VERSION ""

NS_ :

BS_:

BU_:

BO_ 3 gnss_pos: 8 Vector__XXX
 SG_ Latitude : 5|30@0- (1,0) [-536870912|536870911] "ms arc" Vector__XXX
 SG_ Longitude : 38|31@0- (1,0) [-1073741824|1073741823] "ms arc" Vector__XXX

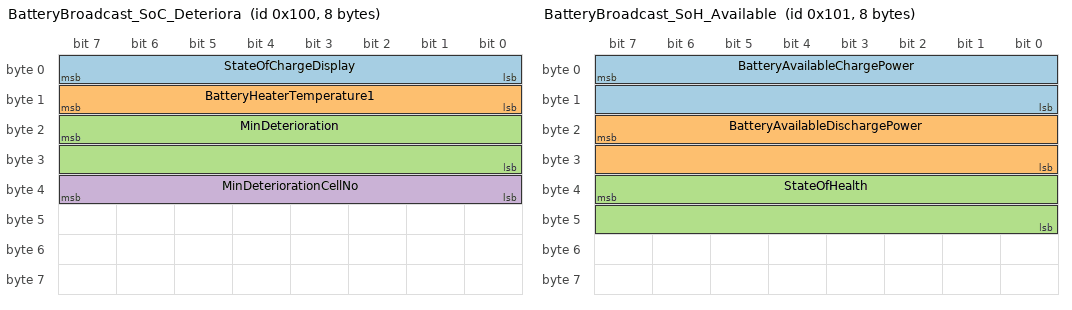
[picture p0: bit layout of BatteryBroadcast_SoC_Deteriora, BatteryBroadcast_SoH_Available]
BO_ 256 BatteryBroadcast_SoC_Deteriora: 8 Vector__XXX
 SG_ StateOfChargeDisplay : 7|8@0+ (0.5,3) [0|0] "%" Vector__XXX
 SG_ BatteryHeaterTemperature1 : 15|8@0- (1,0) [0|0] "degC" Vector__XXX
 SG_ MinDeterioration : 23|16@0+ (0.1,0) [0|100] "%" Vector__XXX
 SG_ MinDeteriorationCellNo : 39|8@0+ (1,0) [0|98] "" Vector__XXX

BO_ 257 BatteryBroadcast_SoH_Available: 8 Vector__XXX
 SG_ BatteryAvailableChargePower : 7|16@0+ (0.01,0) [0|270] "kW" Vector__XXX
 SG_ BatteryAvailableDischargePower : 23|16@0+ (0.01,0) [0|270] "kW" Vector__XXX
 SG_ StateOfHealth : 39|16@0+ (0.1,0) [0|100] "%" Vector__XXX

BO_ 512 BatteryBroadcast_CellV_Modules: 8 Vector__XXX
 SG_ CellVoltage01 m258 : 7|8@0+ (0.02,0) [2.8|4.2] "V" Vector__XXX
 SG_ CellVoltage02 m258 : 15|8@0+ (0.02,0) [2.8|4.2] "V" Vector__XXX
 SG_ CellVoltage03 m258 : 23|8@0+ (0.02,0) [2.8|4.2] "V" Vector__XXX
 SG_ CellVoltage04 m258 : 31|8@0+ (0.02,0) [2.8|4.2] "V" Vector__XXX
 SG_ CellVoltage05 m258 : 39|8@0+ (0.02,0) [2.8|4.2] "V" Vector__XXX
 SG_ CellVoltage06 m258 : 47|8@0+ (0.02,0) [2.8|4.2] "V" Vector__XXX
 SG_ CellVoltage07 m258 : 55|8@0+ (0.02,0) [2.8|4.2] "V" Vector__XXX
 SG_ CellVoltage08 m258 : 63|8@0+ (0.02,0) [2.8|4.2] "V" Vector__XXX

BO_ 513 BatteryBroadcast_CellV_Modul01: 8 Vector__XXX
 SG_ CellVoltage09 : 7|8@0+ (0.02,0) [2.8|4.2] "V" Vector__XXX
 SG_ CellVoltage10 m258 : 15|8@0+ (0.02,0) [2.8|4.2] "V" Vector__XXX
 SG_ CellVoltage11 m258 : 23|8@0+ (0.02,0) [2.8|4.2] "V" Vector__XXX
 SG_ CellVoltage12 m258 : 31|8@0+ (0.02,0) [2.8|4.2] "V" Vector__XXX
 SG_ CellVoltage13 m258 : 39|8@0+ (0.02,0) [2.8|4.2] "V" Vector__XXX
 SG_ CellVoltage14 m258 : 47|8@0+ (0.02,0) [2.8|4.2] "V" Vector__XXX
 SG_ CellVoltage15 m258 : 55|8@0+ (0.02,0) [2.8|4.2] "V" Vector__XXX
 SG_ CellVoltage16 m258 : 63|8@0+ (0.02,0) [2.8|4.2] "V" Vector__XXX

BO_ 514 BatteryBroadcast_CellV_Modul02: 8 Vector__XXX
 SG_ CellVoltage17 : 7|8@0+ (0.02,0) [2.8|4.2] "V" Vector__XXX
 SG_ CellVoltage18 m258 : 15|8@0+ (0.02,0) [2.8|4.2] "V" Vector__XXX
 SG_ CellVoltage19 m258 : 23|8@0+ (0.02,0) [2.8|4.2] "V" Vector__XXX
 SG_ CellVoltage20 : 31|8@0+ (0.02,0) [2.8|4.2] "V" Vector__XXX
 SG_ CellVoltage21 : 39|8@0+ (0.02,0) [2.4|4.8] "V" Vector__XXX
 SG_ CellVoltage22 : 47|8@0+ (0.02,0) [2.4|4.8] "V" Vector__XXX
 SG_ CellVoltage23 : 55|8@0+ (0.02,0) [2.8|4.2] "V" Vector__XXX
 SG_ CellVoltage24 : 63|8@0+ (0.02,0) [2.8|4.2] "V" Vector__XXX

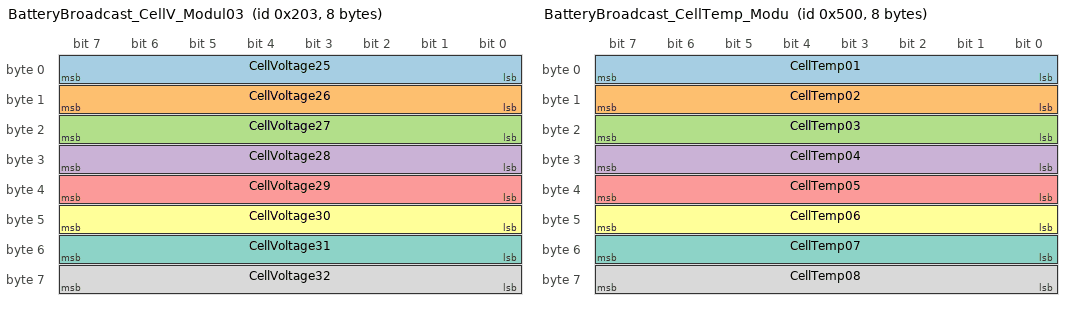
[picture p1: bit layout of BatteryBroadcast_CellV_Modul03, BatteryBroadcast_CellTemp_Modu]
BO_ 515 BatteryBroadcast_CellV_Modul03: 8 Vector__XXX
 SG_ CellVoltage25 : 7|8@0+ (0.02,0) [2.8|4.2] "V" Vector__XXX
 SG_ CellVoltage26 : 15|8@0+ (0.02,0) [2.8|4.2] "V" Vector__XXX
 SG_ CellVoltage27 : 23|8@0+ (0.02,0) [2.8|4.2] "V" Vector__XXX
 SG_ CellVoltage28 : 31|8@0+ (0.02,0) [2.8|4.2] "V" Vector__XXX
 SG_ CellVoltage29 : 39|8@0+ (0.02,0) [2.8|4.2] "V" Vector__XXX
 SG_ CellVoltage30 : 47|8@0+ (0.02,0) [2.8|4.2] "V" Vector__XXX
 SG_ CellVoltage31 : 55|8@0+ (0.02,0) [2.8|4.2] "V" Vector__XXX
 SG_ CellVoltage32 : 63|8@0+ (0.02,0) [2.8|4.2] "V" Vector__XXX

BO_ 768 BatteryBroadcast_Battery_Info_: 8 Vector__XXX
 SG_ MinCellVoltage m257 : 7|8@0+ (0.02,0) [2.8|4.2] "V" Vector__XXX
 SG_ MaxCellVoltage m257 : 15|8@0+ (0.02,0) [2.8|4.2] "V" Vector__XXX
 SG_ StateOfChargeBMS m257 : 55|8@0+ (0.5,3) [0|100] "%" Vector__XXX
 SG_ hasActiveDTC : 63|1@0+ (1,0) [0|1] "" Vector__XXX

BO_ 769 BatteryBroadcast_Battery_Inf01: 8 Vector__XXX
 SG_ BatteryMinTemperature m257 : 7|8@0- (1,0) [0|0] "degC" Vector__XXX
 SG_ BatteryMaxTemperature m257 : 15|8@0- (1,0) [0|0] "degC" Vector__XXX
 SG_ BatteryVoltageAuxillary m257 : 23|8@0+ (0.1,0) [11|14.6] "V" Vector__XXX
 SG_ BatteryFanFeedback m257 : 39|8@0+ (1,0) [0|120] "Hz" Vector__XXX
 SG_ BatteryFanStatus m257 : 47|1@0+ (1,0) [0|0] "" Vector__XXX
 SG_ NormalChargePort m257 : 53|1@0+ (1,0) [0|0] "" Vector__XXX
 SG_ RapidChargePort m257 : 54|1@0+ (1,0) [0|0] "" Vector__XXX

BO_ 770 BatteryBroadcast_Battery_Inf02: 8 Vector__XXX
 SG_ OperatingTime m257 : 7|32@0+ (0.000277778,0) [0|1000000] "hours" Vector__XXX
 SG_ MinCellVoltageCellNo m257 : 39|8@0+ (1,0) [0|0] "" Vector__XXX
 SG_ MaxCellVoltageCellNo m257 : 47|8@0+ (1,0) [0|0] "" Vector__XXX
 SG_ Charging m257 : 55|1@0+ (1,0) [0|0] "" Vector__XXX
 SG_ BMSMainRelay m257 : 48|1@0+ (1,0) [0|0] "" Vector__XXX
 SG_ BMSIgnition m257 : 50|1@0+ (1,0) [0|0] "" Vector__XXX

BO_ 771 BatteryBroadcast_Battery_Inf03: 8 Vector__XXX
 SG_ BatteryDCVoltage m257 : 7|16@0+ (0.1,0) [0|0] "V" Vector__XXX
 SG_ BatteryCurrent m257 : 23|16@0- (0.1,0) [-230|230] "A" Vector__XXX

BO_ 1024 VehicleBroadcast_Temperature_I: 8 Vector__XXX
 SG_ IndoorTemperature m256 : 7|8@0+ (0.5,-40) [-50|50] "degC" Vector__XXX
 SG_ OutdoorTemperature m256 : 15|8@0+ (0.5,-40) [-50|50] "degC" Vector__XXX
 SG_ VehicleSpeed m256 : 23|8@0+ (1,0) [0|200] "kmh" Vector__XXX

BO_ 1025 VehicleBroadCast_Tire_Info: 8 Vector__XXX
 SG_ TirePressureFrontLeft m49163 : 7|8@0+ (0.2,0) [0|120] "psi" Vector__XXX
 SG_ TirePressureFrontRight m49163 : 15|8@0+ (0.2,0) [0|120] "psi" Vector__XXX
 SG_ TirePressureBackLeft m49163 : 23|8@0+ (0.2,0) [0|120] "psi" Vector__XXX
 SG_ TirePressureBackRight m49163 : 31|8@0+ (0.2,0) [0|120] "psi" Vector__XXX
 SG_ TireTemperatureFrontLeft m49163 : 39|8@0+ (1,-50) [-40|65] "degC" Vector__XXX
 SG_ TireTemperatureFrontRight m49163 : 47|8@0+ (1,-50) [-40|65] "degC" Vector__XXX
 SG_ TireTemperatureBackLeft m49163 : 55|8@0+ (1,-50) [-40|65] "degC" Vector__XXX
 SG_ TireTemperatureBackRight m49163 : 63|8@0+ (1,-50) [-40|65] "degC" Vector__XXX

BO_ 1280 BatteryBroadcast_CellTemp_Modu: 8 Vector__XXX
 SG_ CellTemp01 : 7|8@0- (1,0) [-128|127] "degC" Vector__XXX
 SG_ CellTemp02 : 15|8@0- (1,0) [-128|127] "degC" Vector__XXX
 SG_ CellTemp03 : 23|8@0- (1,0) [-128|127] "degC" Vector__XXX
 SG_ CellTemp04 : 31|8@0- (1,0) [-128|127] "degC" Vector__XXX
 SG_ CellTemp05 : 39|8@0- (1,0) [-128|127] "degC" Vector__XXX
 SG_ CellTemp06 : 47|8@0- (1,0) [-128|127] "degC" Vector__XXX
 SG_ CellTemp07 : 55|8@0- (1,0) [-128|127] "degC" Vector__XXX
 SG_ CellTemp08 : 63|8@0- (1,0) [-128|127] "degC" Vector__XXX

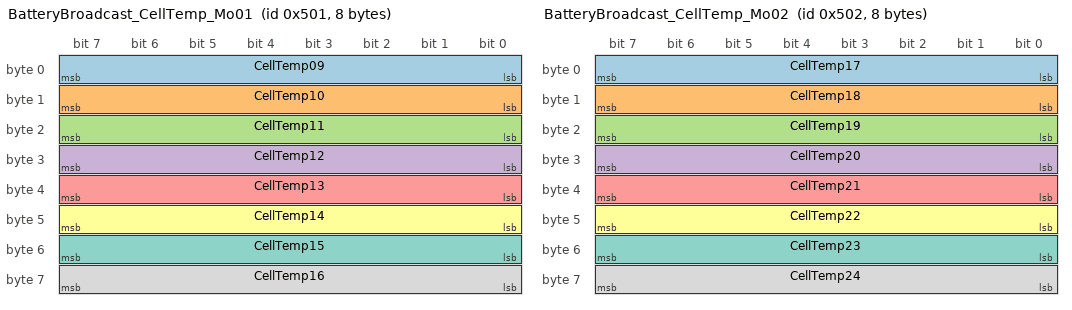
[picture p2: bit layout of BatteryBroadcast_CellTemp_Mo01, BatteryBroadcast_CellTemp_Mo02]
BO_ 1281 BatteryBroadcast_CellTemp_Mo01: 8 Vector__XXX
 SG_ CellTemp09 : 7|8@0- (1,0) [-128|127] "degC" Vector__XXX
 SG_ CellTemp10 : 15|8@0- (1,0) [-128|127] "degC" Vector__XXX
 SG_ CellTemp11 : 23|8@0- (1,0) [-128|127] "degC" Vector__XXX
 SG_ CellTemp12 : 31|8@0- (1,0) [-128|127] "degC" Vector__XXX
 SG_ CellTemp13 : 39|8@0- (1,0) [-128|127] "degC" Vector__XXX
 SG_ CellTemp14 : 47|8@0- (1,0) [-128|127] "degC" Vector__XXX
 SG_ CellTemp15 : 55|8@0- (1,0) [-128|127] "degC" Vector__XXX
 SG_ CellTemp16 : 63|8@0- (1,0) [-128|127] "degC" Vector__XXX

BO_ 1282 BatteryBroadcast_CellTemp_Mo02: 8 Vector__XXX
 SG_ CellTemp17 : 7|8@0- (1,0) [-128|127] "degC" Vector__XXX
 SG_ CellTemp18 : 15|8@0- (1,0) [-128|127] "degC" Vector__XXX
 SG_ CellTemp19 : 23|8@0- (1,0) [-128|127] "degC" Vector__XXX
 SG_ CellTemp20 : 31|8@0- (1,0) [-128|127] "degC" Vector__XXX
 SG_ CellTemp21 : 39|8@0- (1,0) [-128|127] "degC" Vector__XXX
 SG_ CellTemp22 : 47|8@0- (1,0) [-128|127] "degC" Vector__XXX
 SG_ CellTemp23 : 55|8@0- (1,0) [-128|127] "degC" Vector__XXX
 SG_ CellTemp24 : 63|8@0- (1,0) [-128|127] "degC" Vector__XXX

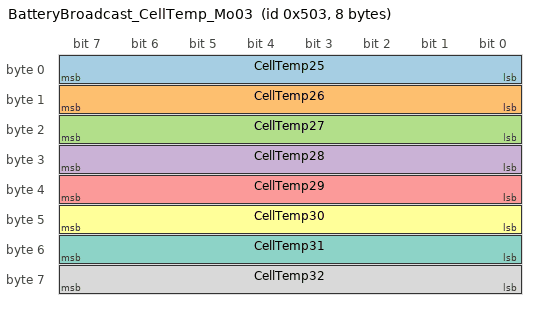
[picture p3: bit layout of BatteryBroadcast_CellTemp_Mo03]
BO_ 1283 BatteryBroadcast_CellTemp_Mo03: 8 Vector__XXX
 SG_ CellTemp25 : 7|8@0- (1,0) [-128|127] "degC" Vector__XXX
 SG_ CellTemp26 : 15|8@0- (1,0) [-128|127] "degC" Vector__XXX
 SG_ CellTemp27 : 23|8@0- (1,0) [-128|127] "degC" Vector__XXX
 SG_ CellTemp28 : 31|8@0- (1,0) [-128|127] "degC" Vector__XXX
 SG_ CellTemp29 : 39|8@0- (1,0) [-128|127] "degC" Vector__XXX
 SG_ CellTemp30 : 47|8@0- (1,0) [-128|127] "degC" Vector__XXX
 SG_ CellTemp31 : 55|8@0- (1,0) [-128|127] "degC" Vector__XXX
 SG_ CellTemp32 : 63|8@0- (1,0) [-128|127] "degC" Vector__XXX

BA_DEF_ BO_  "GenMsgCycleTime" INT 0 10000;
BA_DEF_DEF_  "GenMsgCycleTime" 0;
BA_ "GenMsgCycleTime" BO_ 3 250;
BA_ "GenMsgCycleTime" BO_ 256 500;
BA_ "GenMsgCycleTime" BO_ 257 500;
BA_ "GenMsgCycleTime" BO_ 512 500;
BA_ "GenMsgCycleTime" BO_ 513 500;
BA_ "GenMsgCycleTime" BO_ 514 500;
BA_ "GenMsgCycleTime" BO_ 515 500;
BA_ "GenMsgCycleTime" BO_ 768 500;
BA_ "GenMsgCycleTime" BO_ 769 500;
BA_ "GenMsgCycleTime" BO_ 770 500;
BA_ "GenMsgCycleTime" BO_ 771 500;
BA_ "GenMsgCycleTime" BO_ 1024 500;
BA_ "GenMsgCycleTime" BO_ 1025 500;
BA_ "GenMsgCycleTime" BO_ 1280 500;
BA_ "GenMsgCycleTime" BO_ 1281 500;
BA_ "GenMsgCycleTime" BO_ 1282 500;
BA_ "GenMsgCycleTime" BO_ 1283 500;
